# XHSC_HC32F420 register map
Vendor: XHSC Co.Ltd; Series: ARMCM4; File version: 1.2
CPU: CM4 r0p0, little endian, no MPU, no FPU, 3 interrupt priority bits
Registers are 32-bit, read-write, reset 0x0 unless marked. A register's access mark holds for its fields unless they carry their own. Offsets are from the block's base; [hi:lo] are bit positions; {n}, {i} and the like mark numbered series.

## ATIM3MODE23
Base 0x40006C00; alternate view of ATIM3MODE0
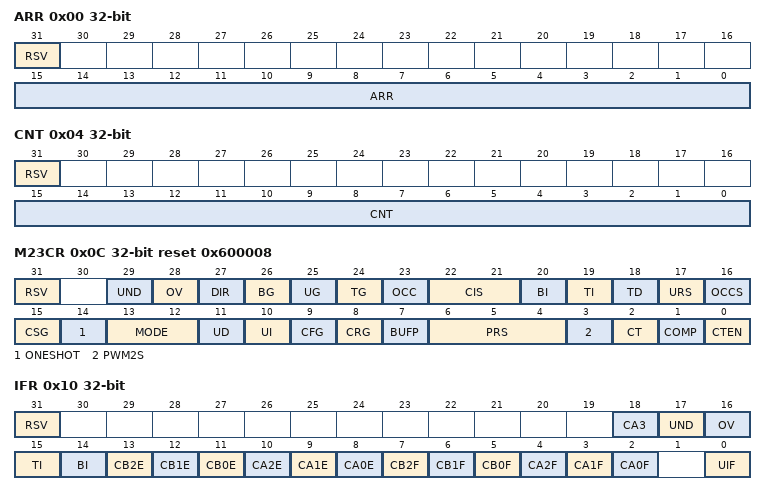
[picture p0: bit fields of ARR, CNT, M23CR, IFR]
0x00 ARR (reset mask 0xFFFF)
  [31] RSV, [15:0] ARR
0x04 CNT (reset mask 0xFFFF)
  [31] RSV, [15:0] CNT
0x0C M23CR reset 0x600008 (reset mask 0xFFFFFFF)
  [31] RSV, [29] UND, [28] OV, [27] DIR, [26] BG wo, [25] UG wo, [24] TG wo, [23] OCC, [22:21] CIS, [20] BI, [19] TI, [18] TD, [17] URS, [16] OCCS, [15] CSG, [14] ONESHOT, [13:12] MODE, [11] UD, [10] UI, [9] CFG, [8] CRG, [7] BUFP, [6:4] PRS, [3] PWM2S, [2] CT, [1] COMP, [0] CTEN
0x10 IFR ro (reset mask 0xFFFD)
  [31] RSV, [18] CA3, [17] UND, [16] OV, [15] TI, [14] BI, [13] CB2E, [12] CB1E, [11] CB0E, [10] CA2E, [9] CA1E, [8] CA0E, [7] CB2F, [6] CB1F, [5] CB0F, [4] CA2F, [3] CA1F, [2] CA0F, [0] UIF
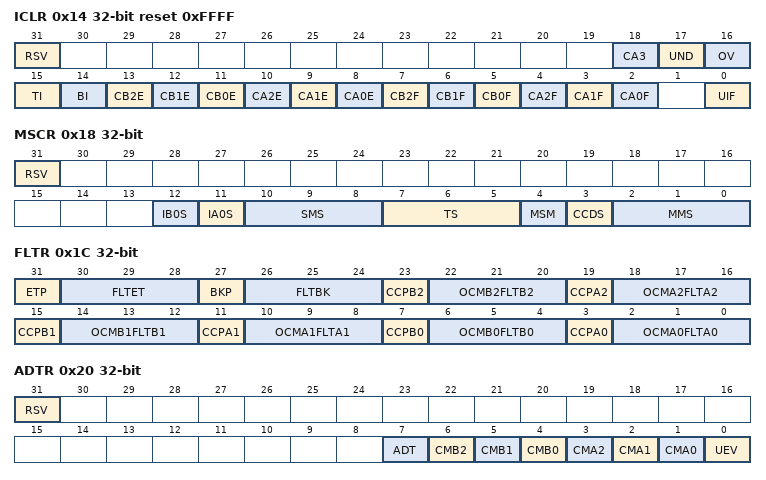
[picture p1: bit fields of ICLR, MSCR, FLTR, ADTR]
0x14 ICLR wo reset 0xFFFF (reset mask 0xFFFD)
  [31] RSV rw, [18] CA3 rw, [17] UND rw, [16] OV rw, [15] TI rw, [14] BI rw, [13] CB2E rw, [12] CB1E rw, [11] CB0E rw, [10] CA2E rw, [9] CA1E rw, [8] CA0E rw, [7] CB2F rw, [6] CB1F rw, [5] CB0F rw, [4] CA2F rw, [3] CA1F rw, [2] CA0F rw, [0] UIF rw
0x18 MSCR (reset mask 0x1FFF)
  [31] RSV, [12] IB0S, [11] IA0S, [10:8] SMS, [7:5] TS, [4] MSM, [3] CCDS, [2:0] MMS
0x1C FLTR
  [31] ETP, [30:28] FLTET, [27] BKP, [26:24] FLTBK, [23] CCPB2, [22:20] OCMB2FLTB2, [19] CCPA2, [18:16] OCMA2FLTA2, [15] CCPB1, [14:12] OCMB1FLTB1, [11] CCPA1, [10:8] OCMA1FLTA1, [7] CCPB0, [6:4] OCMB0FLTB0, [3] CCPA0, [2:0] OCMA0FLTA0
0x20 ADTR (reset mask 0xFF)
  [31] RSV, [7] ADT, [6] CMB2, [5] CMB1, [4] CMB0, [3] CMA2, [2] CMA1, [1] CMA0, [0] UEV
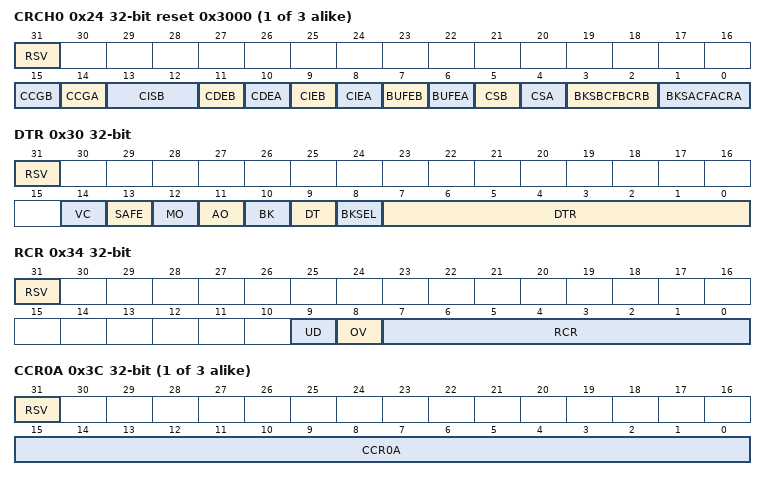
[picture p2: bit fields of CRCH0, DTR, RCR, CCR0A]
{0x24+4i} CRCH{i} reset 0x3000 (reset mask 0xFFFF) (i=0..2)
  [31] RSV, [15] CCGB, [14] CCGA, [13:12] CISB, [11] CDEB, [10] CDEA, [9] CIEB, [8] CIEA, [7] BUFEB, [6] BUFEA, [5] CSB, [4] CSA, [3:2] BKSBCFBCRB, [1:0] BKSACFACRA
0x30 DTR (reset mask 0xFFFF)
  [31] RSV, [14] VC, [13] SAFE, [12] MO, [11] AO, [10] BK, [9] DT, [8] BKSEL, [7:0] DTR
0x34 RCR (reset mask 0xFF)
  [31] RSV, [9] UD, [8] OV, [7:0] RCR
{0x3C+8i} CCR{i}A (reset mask 0xFFFF) (i=0..2)
  [31] RSV, [15:0] CCR{i}A
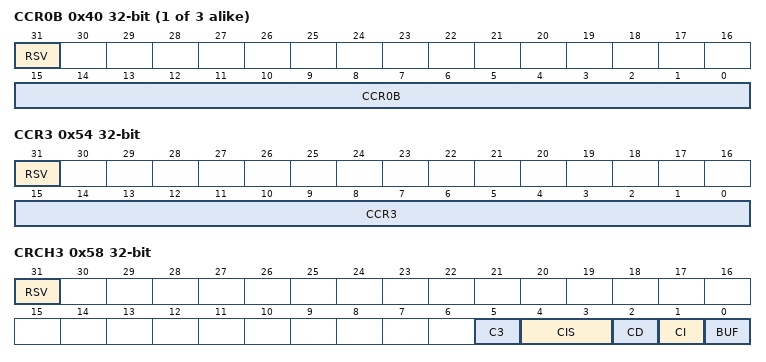
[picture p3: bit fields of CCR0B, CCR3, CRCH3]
{0x40+8i} CCR{i}B (reset mask 0xFFFF) (i=0..2)
  [31] RSV, [15:0] CCR{i}B
0x54 CCR3 (reset mask 0xFFFF)
  [31] RSV, [15:0] CCR3
0x58 CRCH3 (reset mask 0xFFFF)
  [31] RSV, [5] C3, [4:3] CIS, [2] CD, [1] CI, [0] BUF

## BTIM0 — desc BTIM
Base 0x40005000
Same registers: BTIM1 0x40005100, BTIM2 0x40005200
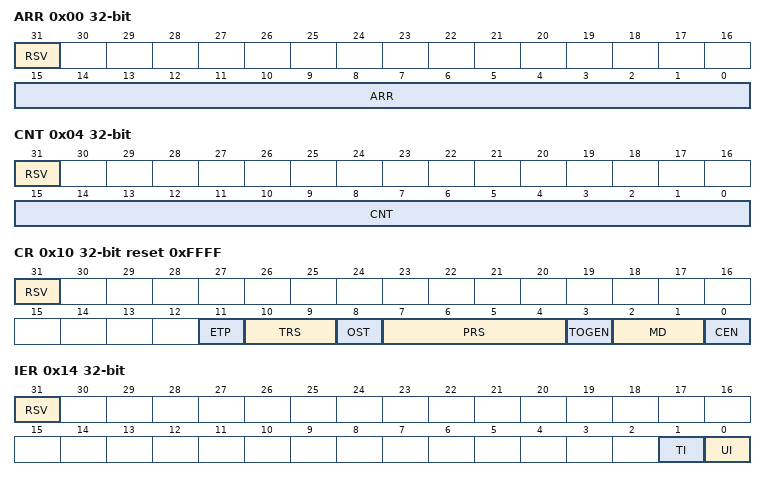
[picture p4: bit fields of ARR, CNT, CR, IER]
0x00 ARR (reset mask 0xFFFF)
  [31] RSV, [15:0] ARR
0x04 CNT (reset mask 0xFFFF)
  [31] RSV, [15:0] CNT
0x10 CR reset 0xFFFF (reset mask 0xFFFF)
  [31] RSV, [11] ETP, [10:9] TRS, [8] OST, [7:4] PRS, [3] TOGEN, [2:1] MD, [0] CEN
0x14 IER (reset mask 0xF)
  [31] RSV, [1] TI, [0] UI
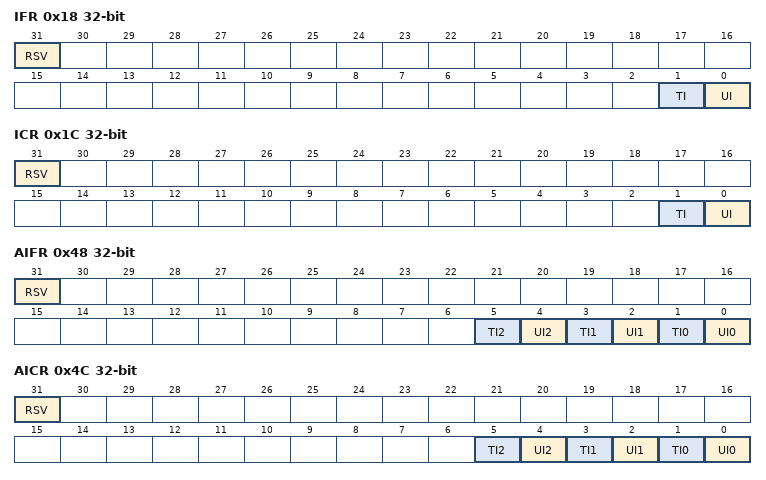
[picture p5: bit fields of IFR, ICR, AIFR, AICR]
0x18 IFR ro (reset mask 0xF)
  [31] RSV, [1] TI, [0] UI
0x1C ICR (reset mask 0xF)
  [31] RSV, [1] TI, [0] UI
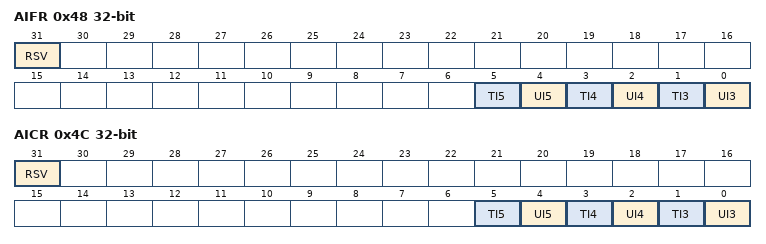
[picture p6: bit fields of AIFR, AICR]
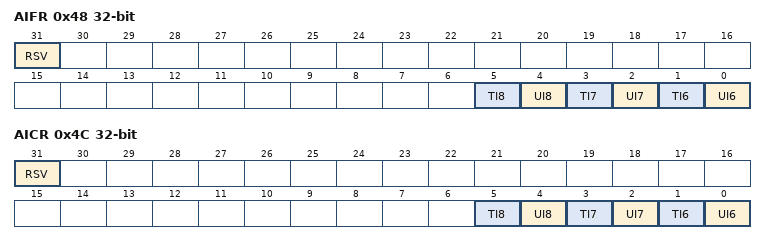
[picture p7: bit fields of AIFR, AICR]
0x48 AIFR ro (reset mask 0xF)
  [31] RSV, [5] TI2, [4] UI2, [3] TI1, [2] UI1, [1] TI0, [0] UI0
0x4C AICR (reset mask 0xF)
  [31] RSV, [5] TI2, [4] UI2, [3] TI1, [2] UI1, [1] TI0, [0] UI0

## BTIM3 — desc BTIM
Base 0x40005400
Same registers: BTIM4 0x40005500, BTIM5 0x40005600
Registers as BTIM0; these are added or differ:
0x48 AIFR ro (reset mask 0xF)
  [31] RSV, [5] TI5, [4] UI5, [3] TI4, [2] UI4, [1] TI3, [0] UI3
0x4C AICR (reset mask 0xF)
  [31] RSV, [5] TI5, [4] UI5, [3] TI4, [2] UI4, [1] TI3, [0] UI3

## BTIM6 — desc BTIM
Base 0x40005800
Same registers: BTIM7 0x40005900, BTIM8 0x40005A00
Registers as BTIM0; these are added or differ:
0x48 AIFR ro (reset mask 0xF)
  [31] RSV, [5] TI8, [4] UI8, [3] TI7, [2] UI7, [1] TI6, [0] UI6
0x4C AICR (reset mask 0xF)
  [31] RSV, [5] TI8, [4] UI8, [3] TI7, [2] UI7, [1] TI6, [0] UI6

## CRC
Base 0x40020800
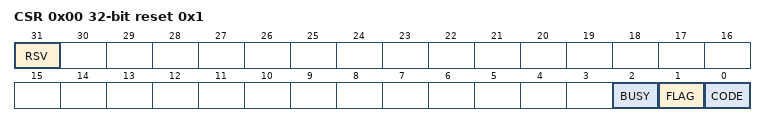
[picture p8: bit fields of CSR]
0x00 CSR ro reset 0x1 (reset mask 0x3)
  [31] RSV, [2] BUSY, [1] FLAG, [0] CODE
0x04 RESULT
0x80 DR wo
